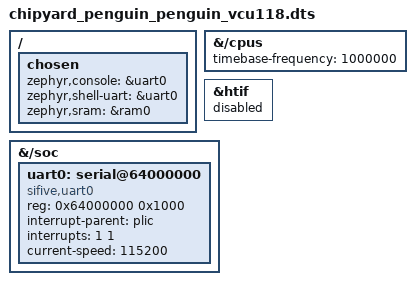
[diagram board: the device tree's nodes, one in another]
/*
 * SPDX-License-Identifier: Apache-2.0
 *
 * Variant "vcu118": the WHOLE Penguin SoC emulated on a Xilinx VCU118 FPGA
 * (tapeout poster: "Verified bare metal workload correctness on Virtex
 * Ultrascale VCU118 (Bare FPGA)", "MMIO & DRAM size re-configured").
 *
 * The real Penguin-on-VCU118 Chipyard config is NOT in the lab repo. Every
 * value below is taken from the GENERIC Chipyard VCU118 flow
 * (fpga/src/main/scala/vcu118/Configs.scala, WithVCU118Tweaks and
 * WithDefaultPeripherals) and is therefore an assumption for Penguin:
 *   - UART (sifive,uart0) at 0x6400_0000, PLIC source 1 (sdboot platform.h:
 *     UART_INT_BASE 1)                                       [generic, H]
 *   - timebase 1 MHz (DTSTimebase = 1e6)                     [generic, H]
 *   - all buses 100 MHz by default (WithFPGAFrequency(100))  [generic, H]
 *   - DRAM at 0x8000_0000, size = VCU118DDRSize (2 GiB assumed; Zephyr only
 *     describes 256 MiB, as on the base board)               [assumed]
 *   - CLINT 0x0200_0000 / PLIC 0x0C00_0000 / scratchpad 0x0800_0000 /
 *     core: kept from penguin.dtsi; the poster says MMIO was re-configured,
 *     so these may have MOVED in the real bitstream.        [UNVERIFIED]
 *   - Atlas: penguin.dtsi (npu@20000) enables the node for EVERY variant,
 *     including this one, but whether Atlas is really in the emulated
 *     design is unknown. hw_probe's Atlas section defaults off here
 *     (PROBE_ATLAS). Deliberately NOT disabled in this file: whether the
 *     generic vcu118 should disable it is a pending user decision.
 *
 * Boot flow: sdboot loads a raw image to 0x8000_0000 and jumps there, or load
 * over JTAG. There is no HTIF host, so the console is the UART and
 * chipyard_sim_exit() prints "*** EXIT <code> ***" and halts.
 */

#include <chipyard/penguin.dtsi>

/ {
	chosen {
		zephyr,console = &uart0;
		zephyr,shell-uart = &uart0;
		zephyr,sram = &ram0;
	};
};

/* mtime / DTSTimebase = 1 MHz on the Chipyard VCU118 flow (not 500 kHz).
 * Must equal CONFIG_SYS_CLOCK_HW_CYCLES_PER_SEC (soc Kconfig.defconfig sets
 * it when CHIPYARD_FPGA_EMULATION is on).
 */

&{/cpus} {
	timebase-frequency = <1000000>;
};

/* No HTIF host on an FPGA. */
&htif {
	status = "disabled";
};

/* The generic VCU118 UART is at 0x6400_0000, not 0x1002_0000: replace the
 * node (not just reg) so the unit address matches. */
/delete-node/ &uart0;

&{/soc} {
	uart0: serial@64000000 {
		compatible = "sifive,uart0";
		reg = <0x64000000 0x1000>;
		reg-names = "control";
		interrupt-parent = <&plic>;
		interrupts = <1 1>;	/* PLIC source 1 (sdboot UART_INT_BASE), priority 1; INFERRED for Penguin */
		current-speed = <115200>;
		status = "okay";
	};
};

/* DRAM: VCU118DDRSize (fpga-shells; not checked out here) is assumed to be
 * 2 GiB. We keep the base board's 256 MiB: that is all Zephyr needs and it
 * stays valid if the bitstream resizes DRAM. */
